AUTOSAR XML (schema 00047)
package /ASW_DCM
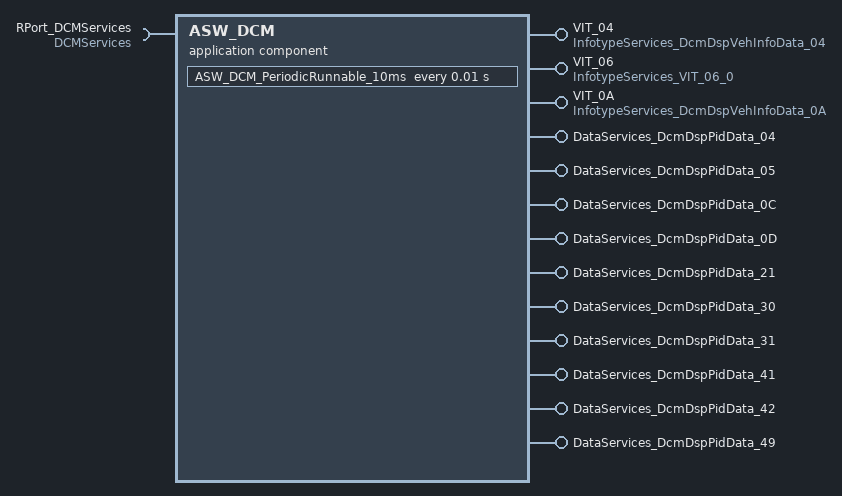
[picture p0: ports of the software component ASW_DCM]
  application sw component type ASW_DCM
    require port RPort_DCMServices: required-interface=DCMServices
    13 x provide port:
      VIT_04: provided-interface=InfotypeServices_DcmDspVehInfoData_04
      VIT_06: provided-interface=InfotypeServices_VIT_06_0
      VIT_0A: provided-interface=InfotypeServices_DcmDspVehInfoData_0A
      DataServices_DcmDspPidData_04: provided-interface=DataServices_DcmDspPidData_04
      DataServices_DcmDspPidData_05: provided-interface=DataServices_DcmDspPidData_05
      DataServices_DcmDspPidData_0C: provided-interface=DataServices_DcmDspPidData_0C
      DataServices_DcmDspPidData_0D: provided-interface=DataServices_DcmDspPidData_0D
      DataServices_DcmDspPidData_21: provided-interface=DataServices_DcmDspPidData_21
      DataServices_DcmDspPidData_30: provided-interface=DataServices_DcmDspPidData_30
      DataServices_DcmDspPidData_31: provided-interface=DataServices_DcmDspPidData_31
      DataServices_DcmDspPidData_41: provided-interface=DataServices_DcmDspPidData_41
      DataServices_DcmDspPidData_42: provided-interface=DataServices_DcmDspPidData_42
      DataServices_DcmDspPidData_49: provided-interface=DataServices_DcmDspPidData_49
    behavior IB_Diag_SWC: data-type-mapping=[DTS_DcmDiagnosticSessionControl, ComMModeMapping, DTS_DcmEcuReset, DTS_DcmControlDTCSetting]
      timing event TE_ASW_DCM: start-on-event=ASW_DCM_PeriodicRunnable_10ms, period=0.01
      13 x operation invoked event:
        OperationInvokedEvent_VIT04: start-on-event=RunnableEntity_VIT_04, operation=VIT_04.GetInfotypeValueData
        OperationInvokedEvent_VIT_06: start-on-event=RunnableEntity_VIT_06, operation=VIT_06.GetInfotypeValueData
        OperationInvokedEvent_VIT_0A: start-on-event=RunnableEntity_VIT_0A, operation=VIT_0A.GetInfotypeValueData
        OIE_RoutineServices_DataServices_R_PID_04_ReadData: start-on-event=DataServices_R_PID_04_ReadData, operation=DataServices_DcmDspPidData_04.ReadData
        OIE_RoutineServices_DataServices_R_PID_05_ReadData: start-on-event=DataServices_R_PID_05_ReadData, operation=DataServices_DcmDspPidData_05.ReadData
        OIE_RoutineServices_DataServices_R_PID_0C_ReadData: start-on-event=DataServices_R_PID_0C_ReadData, operation=DataServices_DcmDspPidData_0C.ReadData
        OIE_RoutineServices_DataServices_R_PID_0D_ReadData: start-on-event=DataServices_R_PID_0D_ReadData, operation=DataServices_DcmDspPidData_0D.ReadData
        OIE_RoutineServices_DataServices_R_PID_21_ReadData: start-on-event=DataServices_R_PID_21_ReadData, operation=DataServices_DcmDspPidData_21.ReadData
        OIE_RoutineServices_DataServices_R_PID_30_ReadData: start-on-event=DataServices_R_PID_30_ReadData, operation=DataServices_DcmDspPidData_30.ReadData
        OIE_RoutineServices_DataServices_R_PID_31_ReadData: start-on-event=DataServices_R_PID_31_ReadData, operation=DataServices_DcmDspPidData_31.ReadData
        OIE_RoutineServices_DataServices_R_PID_41_ReadData: start-on-event=DataServices_R_PID_41_ReadData, operation=DataServices_DcmDspPidData_41.ReadData
        OIE_RoutineServices_DataServices_R_PID_42_ReadData: start-on-event=DataServices_R_PID_42_ReadData, operation=DataServices_DcmDspPidData_42.ReadData
        OIE_RoutineServices_DataServices_R_PID_49_ReadData: start-on-event=DataServices_R_PID_49_ReadData, operation=DataServices_DcmDspPidData_49.ReadData
      14 x runnable:
        ASW_DCM_PeriodicRunnable_10ms: symbol=ASW_DCM_PeriodicRunnable_10ms_func
        RunnableEntity_VIT_04: symbol=RunnableEntity_0_VIT_04
        RunnableEntity_VIT_06: symbol=RunnableEntity_0_func_vit_06
        RunnableEntity_VIT_0A: symbol=RunnableEntity_0_func_VIT_0A
        DataServices_R_PID_04_ReadData
        DataServices_R_PID_05_ReadData
        DataServices_R_PID_0C_ReadData
        DataServices_R_PID_0D_ReadData
        DataServices_R_PID_21_ReadData
        DataServices_R_PID_30_ReadData
        DataServices_R_PID_31_ReadData
        DataServices_R_PID_41_ReadData
        DataServices_R_PID_42_ReadData
        DataServices_R_PID_49_ReadData
